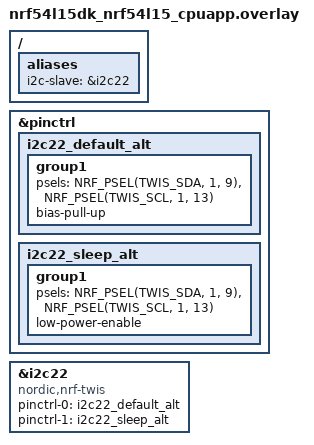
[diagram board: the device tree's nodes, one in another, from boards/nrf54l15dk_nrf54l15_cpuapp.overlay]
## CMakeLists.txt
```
# SPDX-License-Identifier: Apache-2.0

cmake_minimum_required(VERSION 3.20.0)

find_package(Zephyr REQUIRED HINTS $ENV{ZEPHYR_BASE})
project(twi_slave)

target_sources(app PRIVATE src/main.c)
```

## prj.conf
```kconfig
CONFIG_I2C=y
CONFIG_I2C_TARGET=y
CONFIG_I2C_TARGET_BUFFER_MODE=y
```

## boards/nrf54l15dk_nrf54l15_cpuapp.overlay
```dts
/*
 * Copyright 2024 Nordic Semiconductor ASA
 * SPDX-License-Identifier: Apache-2.0
 *
 * nRF54L15DK - TWI Slave overlay
 *
 * Uses i2c22 (TWIS) as the I2C slave, address 0x54.
 *
 * Physical wiring to the master board:
 *   Slave P1.09  SDA  ----  Master P1.08  SDA
 *   Slave P1.13  SCL  ----  Master P1.12  SCL
 *   GND               ----  GND
 *
 * NOTE: Slave uses P1.09/P1.13 to avoid conflict with DK buttons.
 *
 * status = "okay" is required so that pinctrl_apply_state() can
 * configure P1.09/P1.13 through the nRF54L crossbar.
 * TWIS pins must use NRF_PSEL(TWIS_SDA/SCL) — not TWIM — as the
 * crossbar function selectors are different for slave vs master.
 */

/ {
        aliases {
                i2c-slave = &i2c22;
        };
};

&pinctrl {
        i2c22_default_alt: i2c22_default_alt {
                group1 {
                        psels = <NRF_PSEL(TWIS_SDA, 1, 9)>,
                                <NRF_PSEL(TWIS_SCL, 1, 13)>;
                        bias-pull-up;
                };
        };

        i2c22_sleep_alt: i2c22_sleep_alt {
                group1 {
                        psels = <NRF_PSEL(TWIS_SDA, 1, 9)>,
                                <NRF_PSEL(TWIS_SCL, 1, 13)>;
                        low-power-enable;
                };
        };
};

&i2c22 {
        compatible = "nordic,nrf-twis";
        status = "okay";
        pinctrl-0 = <&i2c22_default_alt>;
        pinctrl-1 = <&i2c22_sleep_alt>;
        pinctrl-names = "default", "sleep";
};
```

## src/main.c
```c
#include <zephyr/kernel.h>
#include <zephyr/device.h>
#include <zephyr/drivers/i2c.h>
#include <zephyr/sys/printk.h>
#include <string.h>

#define NODE_TWIS   DT_ALIAS(i2c_slave)
#define SLAVE_ADDR  0x54
#define BUFFER_SIZE 4

static uint8_t slave_buf[BUFFER_SIZE];

#ifdef CONFIG_I2C_TARGET_BUFFER_MODE

static int target_buf_read_requested(struct i2c_target_config *config,
                                     uint8_t **buf, uint32_t *len)
{
        *buf = slave_buf;
        *len = BUFFER_SIZE;
        printk("TWIS: read request\n");
        return 0;
}

static void target_buf_write_received(struct i2c_target_config *config,
                                      uint8_t *buf, uint32_t len)
{
        uint32_t to_copy = MIN(len, (uint32_t)BUFFER_SIZE);
        memcpy(slave_buf, buf, to_copy);

        uint32_t value = (uint32_t)slave_buf[0]
                       | ((uint32_t)slave_buf[1] <<  8)
                       | ((uint32_t)slave_buf[2] << 16)
                       | ((uint32_t)slave_buf[3] << 24);
        printk("TWIS: write done - counter = %u\n", value);
}

static const struct i2c_target_callbacks target_callbacks = {
        .buf_read_requested = target_buf_read_requested,
        .buf_write_received = target_buf_write_received,
};

#endif

static struct i2c_target_config target_cfg = {
        .address   = SLAVE_ADDR,
#ifdef CONFIG_I2C_TARGET_BUFFER_MODE
        .callbacks = &target_callbacks,
#endif
};

int main(void)
{
        const struct device *dev = DEVICE_DT_GET(NODE_TWIS);
        int ret;

        printk("=== TWI Slave starting (addr 0x%02X) ===\n", SLAVE_ADDR);

        if (!device_is_ready(dev)) {
                printk("ERROR: TWIS device not ready\n");
                return -ENODEV;
        }

        ret = i2c_target_register(dev, &target_cfg);
        if (ret != 0) {
                printk("ERROR: i2c_target_register failed (%d)\n", ret);
                return ret;
        }

        printk("TWI Slave ready - waiting for master...\n");

        return 0;
}
```
